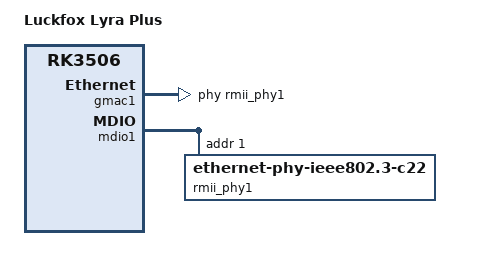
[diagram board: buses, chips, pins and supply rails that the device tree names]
// SPDX-License-Identifier: (GPL-2.0+ OR MIT)

/dts-v1/;
#include "rk3506-luckfox-lyra.dtsi"

/ {
	model = "Luckfox Lyra Plus";
	compatible = "luckfox,lyra-plus", "luckfox,lyra", "rockchip,rk3506";

	aliases {
		ethernet0 = &gmac1;
	};
};

&gmac1 {
	assigned-clocks = <&cru CLK_MAC1>;
	assigned-clock-rates = <50000000>;
	clock_in_out = "output";
	phy-handle = <&rmii_phy1>;
	pinctrl-names = "default";
	pinctrl-0 = <&eth_rmii1_miim>, <&eth_rmii1_tx_bus2>,
		    <&eth_rmii1_rx_bus2>, <&eth_rmii1_clk>;
	status = "okay";
};

&mdio1 {
	rmii_phy1: ethernet-phy@1 {
		compatible = "ethernet-phy-ieee802.3-c22";
		reg = <1>;
	};
};
